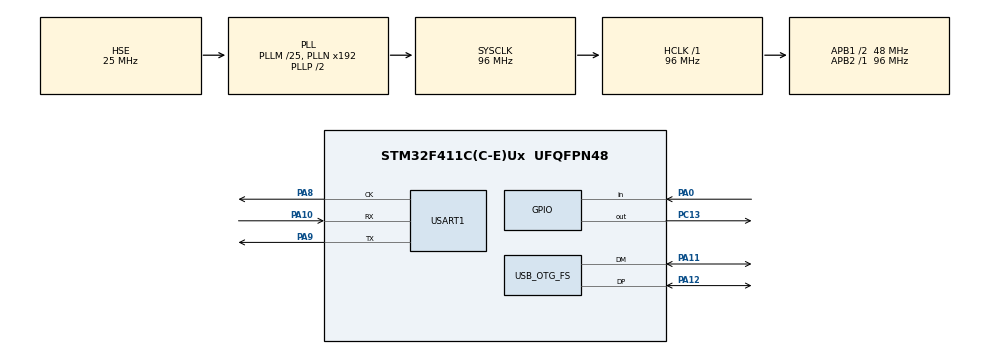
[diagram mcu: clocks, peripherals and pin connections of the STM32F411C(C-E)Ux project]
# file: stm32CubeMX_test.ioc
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Mcu.Family=STM32F4
Mcu.Name=STM32F411C(C-E)Ux
Mcu.Package=UFQFPN48
NVIC.OTG_FS_IRQn=true\:0\:0\:false\:false\:true\:false\:true\:true
NVIC.PriorityGroup=NVIC_PRIORITYGROUP_4
PA0-WKUP.Signal=GPIO_Input
PA10.Mode=Synchronous
PA10.Signal=USART1_RX
PA11.Mode=Device_Only
PA11.Signal=USB_OTG_FS_DM
PA12.Mode=Device_Only
PA12.Signal=USB_OTG_FS_DP
PA8.Mode=Synchronous
PA8.Signal=USART1_CK
PA9.Mode=Synchronous
PA9.Signal=USART1_TX
PC13-ANTI_TAMP.PinState=GPIO_PIN_RESET
PC13-ANTI_TAMP.Signal=GPIO_Output
PH0\ -\ OSC_IN.Mode=HSE-External-Oscillator
PH0\ -\ OSC_IN.Signal=RCC_OSC_IN
PH1\ -\ OSC_OUT.Mode=HSE-External-Oscillator
PH1\ -\ OSC_OUT.Signal=RCC_OSC_OUT
ProjectManager.HeapSize=0x1000
ProjectManager.StackSize=0x800
ProjectManager.TargetToolchain=STM32CubeIDE
RCC.48MHZClocksFreq_Value=48000000
RCC.AHBFreq_Value=96000000
RCC.APB1CLKDivider=RCC_HCLK_DIV2
RCC.APB1Freq_Value=48000000
RCC.APB1TimFreq_Value=96000000
RCC.APB2Freq_Value=96000000
RCC.APB2TimFreq_Value=96000000
RCC.CortexFreq_Value=96000000
RCC.HCLKFreq_Value=96000000
RCC.HSE_VALUE=25000000
RCC.HSI_VALUE=16000000
RCC.LSE_VALUE=32768
RCC.PLLM=25
RCC.SYSCLKFreq_VALUE=96000000
RCC.SYSCLKSource=RCC_SYSCLKSOURCE_PLLCLK
RCC.VCOOutputFreq_Value=192000000
USART1.VirtualMode=VM_SYNC
USB_DEVICE.CLASS_NAME_FS=CDC
USB_DEVICE.VirtualMode=Cdc
USB_DEVICE.VirtualModeFS=Cdc_FS
USB_OTG_FS.VirtualMode=Device_Only
VP_USB_DEVICE_VS_USB_DEVICE_CDC_FS.Mode=CDC_FS
board=custom

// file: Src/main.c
/* USER CODE BEGIN Header */
/**
  ******************************************************************************
  * @file           : main.c
  * @brief          : Main program body
  ******************************************************************************
  * @attention
  *
  * Copyright (c) 2026 STMicroelectronics.
  * All rights reserved.
  *
  * This software is licensed under terms that can be found in the LICENSE file
  * in the root directory of this software component.
  * If no LICENSE file comes with this software, it is provided AS-IS.
  *
  ******************************************************************************
  */
/* USER CODE END Header */
#include "main.h"
#include "usb_device.h"

/* USER CODE BEGIN Includes */
#include <stdbool.h>
/* USER CODE END Includes */

USART_HandleTypeDef husart1;

void SystemClock_Config(void);
static void MX_GPIO_Init(void);
static void MX_USART1_Init(void);

int main(void)
{

  /* MCU Configuration--------------------------------------------------------*/

  /* Reset of all peripherals, Initializes the Flash interface and the Systick. */
  HAL_Init();

  /* Configure the system clock */
  SystemClock_Config();

  /* Initialize all configured peripherals */
  MX_GPIO_Init();
  MX_USB_DEVICE_Init();
  MX_USART1_Init();

  /* Infinite loop */
  /* USER CODE BEGIN WHILE */
  main_cpp();
  while (1)
  {
    /* USER CODE END WHILE */

  }
}

void SystemClock_Config(void)
{
  RCC_OscInitTypeDef RCC_OscInitStruct = {0};
  RCC_ClkInitTypeDef RCC_ClkInitStruct = {0};

  /** Configure the main internal regulator output voltage
  */
  __HAL_RCC_PWR_CLK_ENABLE();
  __HAL_PWR_VOLTAGESCALING_CONFIG(PWR_REGULATOR_VOLTAGE_SCALE1);

  /** Initializes the RCC Oscillators according to the specified parameters
  * in the RCC_OscInitTypeDef structure.
  */
  RCC_OscInitStruct.OscillatorType = RCC_OSCILLATORTYPE_HSE;
  RCC_OscInitStruct.HSEState = RCC_HSE_ON;
  RCC_OscInitStruct.PLL.PLLState = RCC_PLL_ON;
  RCC_OscInitStruct.PLL.PLLSource = RCC_PLLSOURCE_HSE;
  RCC_OscInitStruct.PLL.PLLM = 25;
  RCC_OscInitStruct.PLL.PLLN = 192;
  RCC_OscInitStruct.PLL.PLLP = RCC_PLLP_DIV2;
  RCC_OscInitStruct.PLL.PLLQ = 4;
  if (HAL_RCC_OscConfig(&RCC_OscInitStruct) != HAL_OK)
  {
    Error_Handler();
  }

  /** Initializes the CPU, AHB and APB buses clocks
  */
  RCC_ClkInitStruct.ClockType = RCC_CLOCKTYPE_HCLK|RCC_CLOCKTYPE_SYSCLK
                              |RCC_CLOCKTYPE_PCLK1|RCC_CLOCKTYPE_PCLK2;
  RCC_ClkInitStruct.SYSCLKSource = RCC_SYSCLKSOURCE_PLLCLK;
  RCC_ClkInitStruct.AHBCLKDivider = RCC_SYSCLK_DIV1;
  RCC_ClkInitStruct.APB1CLKDivider = RCC_HCLK_DIV2;
  RCC_ClkInitStruct.APB2CLKDivider = RCC_HCLK_DIV1;

  if (HAL_RCC_ClockConfig(&RCC_ClkInitStruct, FLASH_LATENCY_3) != HAL_OK)
  {
    Error_Handler();
  }
}

static void MX_USART1_Init(void)
{

  husart1.Instance = USART1;
  husart1.Init.BaudRate = 115200;
  husart1.Init.WordLength = USART_WORDLENGTH_8B;
  husart1.Init.StopBits = USART_STOPBITS_1;
  husart1.Init.Parity = USART_PARITY_NONE;
  husart1.Init.Mode = USART_MODE_TX_RX;
  husart1.Init.CLKPolarity = USART_POLARITY_LOW;
  husart1.Init.CLKPhase = USART_PHASE_1EDGE;
  husart1.Init.CLKLastBit = USART_LASTBIT_DISABLE;
  if (HAL_USART_Init(&husart1) != HAL_OK)
  {
    Error_Handler();
  }

}

static void MX_GPIO_Init(void)
{
  GPIO_InitTypeDef GPIO_InitStruct = {0};

  /* GPIO Ports Clock Enable */
  __HAL_RCC_GPIOC_CLK_ENABLE();
  __HAL_RCC_GPIOH_CLK_ENABLE();
  __HAL_RCC_GPIOA_CLK_ENABLE();

  /*Configure GPIO pin Output Level */
  HAL_GPIO_WritePin(GPIOC, GPIO_PIN_13, GPIO_PIN_RESET);

  /*Configure GPIO pin : PC13 */
  GPIO_InitStruct.Pin = GPIO_PIN_13;
  GPIO_InitStruct.Mode = GPIO_MODE_OUTPUT_PP;
  GPIO_InitStruct.Pull = GPIO_NOPULL;
  GPIO_InitStruct.Speed = GPIO_SPEED_FREQ_LOW;
  HAL_GPIO_Init(GPIOC, &GPIO_InitStruct);

  /*Configure GPIO pin : PA0 */
  GPIO_InitStruct.Pin = GPIO_PIN_0;
  GPIO_InitStruct.Mode = GPIO_MODE_INPUT;
  GPIO_InitStruct.Pull = GPIO_NOPULL;
  HAL_GPIO_Init(GPIOA, &GPIO_InitStruct);

}

void Error_Handler(void)
{
  /* USER CODE BEGIN Error_Handler_Debug */
  /* User can add his own implementation to report the HAL error return state */
  /* Keep USB interrupts active so the host can still enumerate the CDC port. */
  while (1)
  {
  }
  /* USER CODE END Error_Handler_Debug */
}
